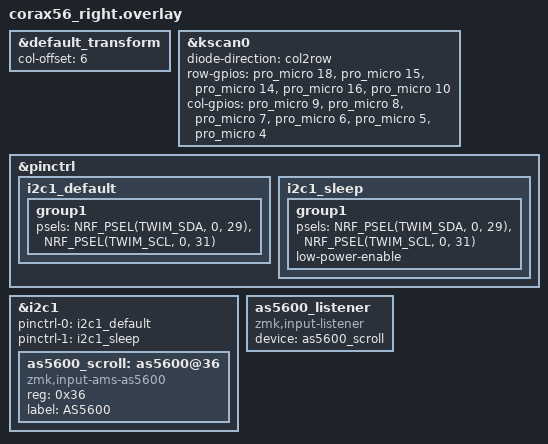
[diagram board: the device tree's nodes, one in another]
#include "corax56.dtsi"

&default_transform {
    col-offset = <6>;
};

&kscan0 {
    diode-direction = "col2row";

    // top to bottom
    row-gpios
        = <&pro_micro 18 (GPIO_ACTIVE_HIGH | GPIO_PULL_DOWN)>  // COL 0 (NUM)
        , <&pro_micro 15 (GPIO_ACTIVE_HIGH | GPIO_PULL_DOWN)>  // COL 1 (UPPER)
        , <&pro_micro 14 (GPIO_ACTIVE_HIGH | GPIO_PULL_DOWN)>  // COL 2 (HOME)
        , <&pro_micro 16 (GPIO_ACTIVE_HIGH | GPIO_PULL_DOWN)>  // COL 3 (LOWER)
        , <&pro_micro 10 (GPIO_ACTIVE_HIGH | GPIO_PULL_DOWN)>  // COL 4 (THUMB + ROT)
        ;

    // left to right    
    col-gpios
        = <&pro_micro 9 GPIO_ACTIVE_HIGH>  // ROW 0 (outer)
        , <&pro_micro 8 GPIO_ACTIVE_HIGH>  // ROW 1 (pinky)
        , <&pro_micro 7 GPIO_ACTIVE_HIGH>  // ROW 2 (ring)
        , <&pro_micro 6 GPIO_ACTIVE_HIGH>  // ROW 3 (middle)
        , <&pro_micro 5 GPIO_ACTIVE_HIGH>  // ROW 4 (index)
        , <&pro_micro 4 GPIO_ACTIVE_HIGH>  // ROW 5 (inner)
        ;
};

// &encoder_right {
//     status = "okay";
// };


&pinctrl {
    i2c1_default: i2c1_default {
        group1 {
            psels = <NRF_PSEL(TWIM_SDA, 0, 29)>, <NRF_PSEL(TWIM_SCL, 0, 31)>;
        };
    };
    i2c1_sleep: i2c1_sleep {
        group1 {
            psels = <NRF_PSEL(TWIM_SDA, 0, 29)>, <NRF_PSEL(TWIM_SCL, 0, 31)>;
            low-power-enable;
        };
    };
};

&i2c1 {
    status = "okay";
    pinctrl-0 = <&i2c1_default>;
    pinctrl-1 = <&i2c1_sleep>;
    pinctrl-names = "default", "sleep";

    as5600_scroll: as5600@36 {
        compatible = "zmk,input-ams-as5600";
        reg = <0x36>;
        label = "AS5600";
        
        status = "okay";


    };
};

as5600_listener {
    compatible = "zmk,input-listener";
    device = <&as5600_scroll>;
};

// &i2c1 {
//     status = "okay";
//     pinctrl-0 = <&i2c1_default>;
//     pinctrl-1 = <&i2c1_sleep>;
//     pinctrl-names = "default", "sleep";
//     as5600_scroll: as5600@36 {
//         compatible = "zmk,input-ams-as5600";
//         reg = <0x36>;
//         label = "AS5600";

//         #sensor-binding-cells = <2>; // ← Diese Zeile ist **Pflicht**, damit `sensor-bindings` funktioniert
//     };
// };





// &pinctrl {
//     spi0_default: spi0_default {
//         group1 {
//             psels = <NRF_PSEL(SPIM_SCK, 0, 29)>,
//                 <NRF_PSEL(SPIM_MOSI, 0, 31)>,
//                 <NRF_PSEL(SPIM_MISO, 0, 25)>;
//         };
//     };
//     spi0_sleep: spi0_sleep {
//         group1 {
//             psels = <NRF_PSEL(SPIM_SCK, 0, 29)>,
//                 <NRF_PSEL(SPIM_MOSI, 0, 31)>,
//                 <NRF_PSEL(SPIM_MISO, 0, 25)>;
//             low-power-enable;
//         };
//     };
// };

// nice_view_spi: &spi0 {
//     compatible = "nordic,nrf-spim";
//     pinctrl-0 = <&spi0_default>;
//     pinctrl-1 = <&spi0_sleep>;
//     pinctrl-names = "default", "sleep";
//     cs-gpios = <&pro_micro 19 GPIO_ACTIVE_HIGH>;
// };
